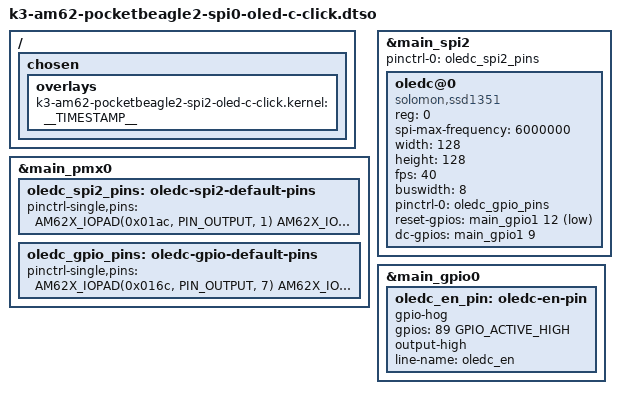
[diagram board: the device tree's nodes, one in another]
// SPDX-License-Identifier: GPL-2.0-only OR MIT
/*
 * DT Overlay for OLED C Click on PocketBeagle v2 (AM62x)
 * Ported from AM335x overlay
 *
 * https://www.mikroe.com/oled-c-click
 */

 /dts-v1/;
/plugin/;

#include <dt-bindings/gpio/gpio.h>
#include <dt-bindings/interrupt-controller/irq.h>
#include "ti/k3-pinctrl.h"

/ {
	chosen {
		overlays {
			k3-am62-pocketbeagle2-spi2-oled-c-click.kernel = __TIMESTAMP__;
		};
	};
};

&main_pmx0 {
	oledc_spi2_pins: oledc-spi2-default-pins {
		pinctrl-single,pins = <
			AM62X_IOPAD(0x01ac, PIN_OUTPUT, 1)  /* P1_06 E19: SPI2_CS0 */
			AM62X_IOPAD(0x01b0, PIN_OUTPUT, 1)  /* P1_08 A20: SPI2_CLK */
			AM62X_IOPAD(0x0194, PIN_INPUT, 1)   /* P1_10 B19: SPI2_D0 (MISO) */
			AM62X_IOPAD(0x0198, PIN_OUTPUT, 1)  /* P1_12 A19: SPI2_D1 (MOSI) */
		>;
	};

	oledc_gpio_pins: oledc-gpio-default-pins {
		pinctrl-single,pins = <
			AM62X_IOPAD(0x016c, PIN_OUTPUT, 7)  /* P1_04 Y18: EN  - GPIO0_89 */
			AM62X_IOPAD(0x019c, PIN_OUTPUT, 7)  /* P2_03 B18: DC  - GPIO1_9 */
			AM62X_IOPAD(0x01a8, PIN_OUTPUT, 7)  /* P1_04 D20: RST - GPIO1_12 */
		>;
	};
};

&main_spi2 {
	status = "okay";
	pinctrl-names = "default";
	pinctrl-0 = <&oledc_spi2_pins>;

	#address-cells = <1>;
	#size-cells = <0>;

	oledc@0 {
		compatible = "solomon,ssd1351";
		reg = <0>;
		spi-max-frequency = <6000000>;
		width = <128>;
		height = <128>;
		fps = <40>;
		buswidth = <8>;

		pinctrl-names = "default";
		pinctrl-0 = <&oledc_gpio_pins>;

		reset-gpios = <&main_gpio1 12 GPIO_ACTIVE_LOW>;
		dc-gpios    = <&main_gpio1 9  GPIO_ACTIVE_HIGH>;
	};
};

&main_gpio0 {
	oledc_en_pin: oledc-en-pin {
		gpio-hog;
		gpios = <89 GPIO_ACTIVE_HIGH>;
		output-high;
		line-name = "oledc_en";
	};
};

